# CM4 register map
CPU: CM4 r0p1, selectable endian, MPU, FPU, 4 interrupt priority bits
Registers are 32-bit, read-write, reset 0x0 unless marked. A register's access mark holds for its fields unless they carry their own. Offsets are from the block's base; [hi:lo] are bit positions.

## MPU — Memory Protection Unit
Base 0xE000ED90
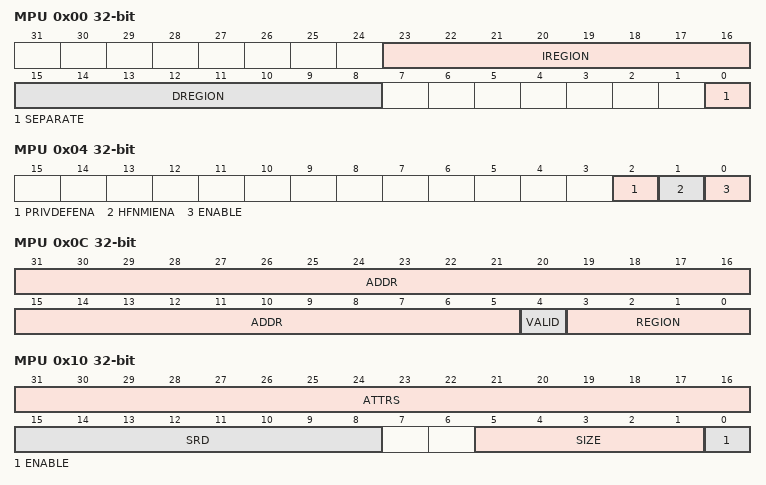
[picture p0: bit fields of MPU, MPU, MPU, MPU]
0x00 MPU Type Register ro — The MPU Type Register indicates how many regions the MPU support
  [23:16] IREGION — Instruction region
  [15:8] DREGION — Number of regions supported by the MPU
  [0] SEPARATE — Indicates support for separate instruction and data address maps. RAZ. ARMv7-M only supports a unified MPU
0x04 MPU Control Register — Enables the MPU, and when the MPU is enabled, controls whether the default memory map is enabled as a background region for privileged accesses, and whether the MPU is enabled for HardFaults, NMIs
  [2] PRIVDEFENA — When the ENABLE bit is set to 1, the meaning of this bit is
    0=Disables the default memory map; 1=Enables the default memory map as a background region for privileged access
  [1] HFNMIENA — When the ENABLE bit is set to 1, controls whether handlers executing with priority less than 0 access memory with the MPU enabled or with the MPU disabled
    0=Disables the MPU for these handlers; 1=Use the MPU for memory accesses by these handlers
  [0] ENABLE — Enables the MPU
    0=The MPU is disabled; 1=The MPU is enabled
0x08 MPU Region Number Register — Selects the region currently accessed by MPU_RBAR and MPU_RASR
  [7:0] REGION — Indicates the memory region accessed by MPU_RBAR and MPU_RASR
0x0C MPU Region Base Address Register — Holds the base address of the region identified by MPU_RNR
  [31:5] ADDR — Base address of the region
  [4] VALID — On writes, indicates whether the region to update is specified by MPU_RNR
    0=Apply the base address update to the region specified by MPU_RNR.REGION; 1=Update MPU_RNR.REGION to the value obtained by zero extending the REGION value specified in this write
  [3:0] REGION — On writes, can specify the number of the region to update
0x10 MPU Region Attribute and Size Register — Defines the size and access behavior of the region identified by MPU_RNR, and enables that region
  [31:16] ATTRS — The MPU Region Attribute field
  [15:8] SRD — Subregion Disable
    0=Subregion enabled; 1=Subregion disabled
  [5:1] SIZE — Indicates the region size
  [0] ENABLE — Enables this region
    0=When the MPU is enabled, this region is disabled; 1=When the MPU is enabled, this region is enabled

## SIG — Software Interrupt Generation
Base 0xE000EF00
0x00 Software Triggered Interrupt Register wo — Provides a mechanism for software to generate an interrupt
  [8:0] INTID — Indicates the interrupt to be triggered

## CMO — Cache Maintenance Operations
Base 0xE000EF50
0x00 Instruction Cache Invalidate All to PoU wo — Invalidate all instruction caches to PoU
  [31:0] Ignored — The value written to this field is ignored. Ignored
0x08 Instruction Cache line Invalidate by Address to PoU wo — Invalidate instruction cache line by address to PoU
0x0C Data Cache line Invalidate by Address to PoC wo — Invalidate data or unified cache line by address to PoC
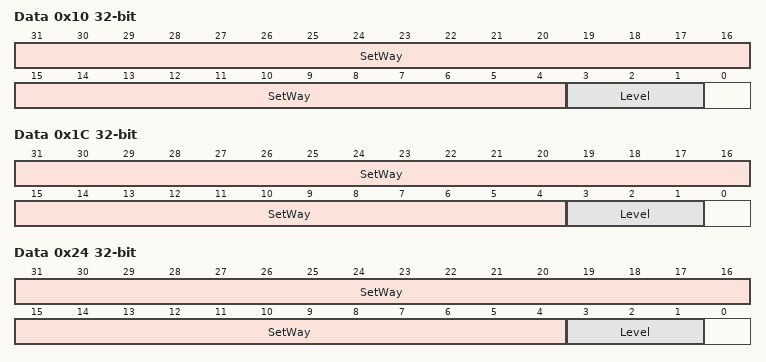
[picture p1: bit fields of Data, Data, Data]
0x10 Data Cache line Invalidate by Set/Way wo — Invalidate data or unified cache line by set/way
  [31:4] SetWay — Cache set/way. Contains two fields: Way, bits[31:32-A], the number of the way to operate on
  [3:1] Level — Cache level. Cache level to operate on, minus 1
0x14 Data Cache line Clean by address to PoU wo — Clean data or unified cache line by address to PoU
0x18 Data Cache line Clean by Address to PoC wo — Clean data or unified cache line by address to PoC
0x1C Data Cache Clean line by Set/Way wo — Clean data or unified cache line by set/way
  [31:4] SetWay — Cache set/way. Contains two fields: Way, bits [31:32-A], the number of the way to operate on
  [3:1] Level — Cache level. Cache level to operate on, minus 1
0x20 Data Cache line Clean and Invalidate by Address to PoC wo — Clean and invalidate data or unified cache line by address to PoC
0x24 Data Cache line Clean and Invalidate by Set/Way wo — Clean and invalidate data or unified cache line by set/way
  [31:4] SetWay — Cache set/way. Contains two fields: Way, bits[31:32-A], the number of the way to operate on
  [3:1] Level — Cache level. Cache level to operate on, minus 1
0x28 Branch Predictor Invalidate All wo — Invalidate all entries from branch predictors
  [31:0] Ignored — Ignored. The value written to this field is ignored

## TPIU — Trace Port Interface Unit
Base 0xE0040000
0x00 Supported Parallel Port Sizes Register ro — Indicates the supported parallel trace port sizes
  [31:0] SWIDTH — SWIDTH[N] represents a trace port width of (N+1)
    0=Width (N+1) not supported; 1=Width (N+1) supported
0x04 Current Parallel Port Size Register — Defines the width of the current parallel trace port
  [31:0] CWIDTH — CWIDTH[N] represents a trace port width of (N+1)
    0=Width (N+1) is not the current trace port width; 1=Width (N+1) is the current trace port width
0x10 Asynchronous Clock Prescaler Register — Defines a prescaler value for the baud rate of the Serial Wire Output (SWO)
  [15:0] SWOSCALER — SWO baud rate prescaler value
0xF0 Selected Pin Protocol Register — Selects the protocol used for trace output
  [1:0] TXMODE — Specifies the protocol for trace output from the TPIU
    0=Parallel trace port mode; 1=Asynchronous SWO, using Manchester encoding; 10=Asynchronous SWO, using NRZ encoding
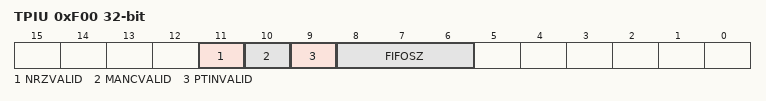
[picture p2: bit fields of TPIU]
0xF00 TPIU Type register ro — Defines the SWO options supported by the TPIU
  [11] NRZVALID — Indicates support for SWO using UART/NRZ encoding
    0=Not supported; 1=Supported
  [10] MANCVALID — Indicates support for SWO using Manchester encoding
    0=Not supported; 1=Supported
  [9] PTINVALID — Indicates support for parallel trace port operation
    0=Supported; 1=Not supported
  [8:6] FIFOSZ — Indicates the minimum implemented size of the TPIU output FIFO for trace data
